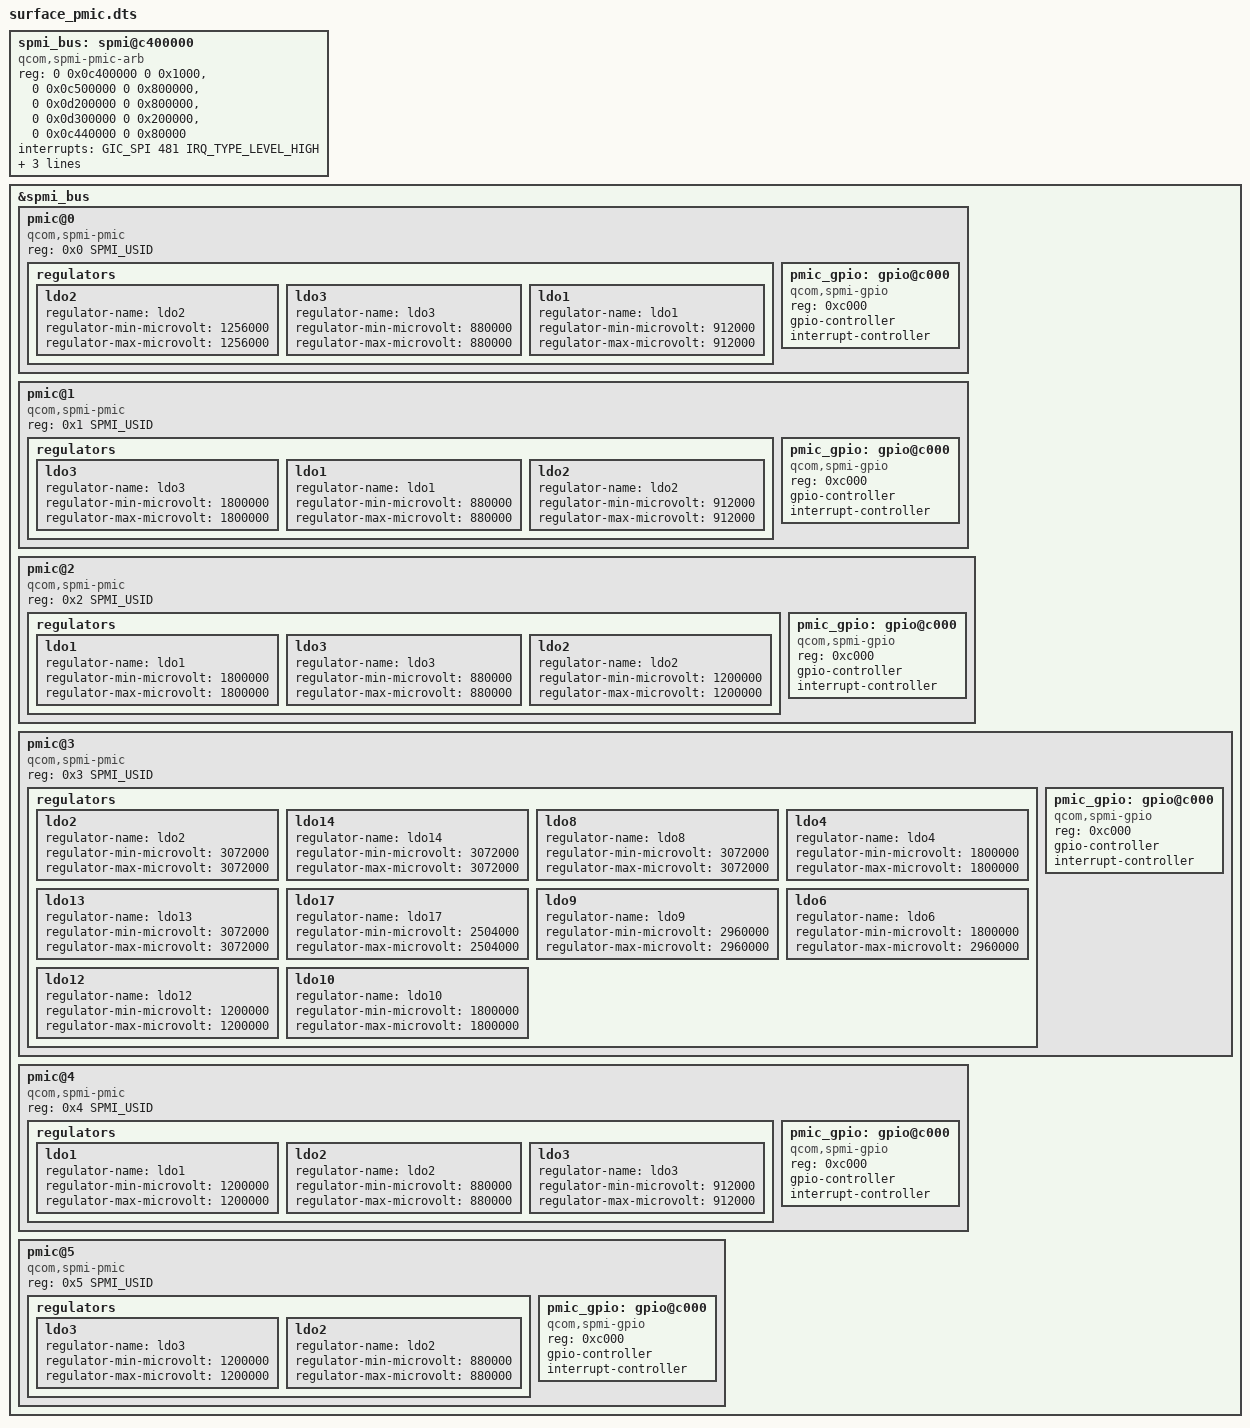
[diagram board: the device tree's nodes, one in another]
// Generated SPMI/PMIC Device Tree Configuration
// Based on parsed ACPI DSL files


spmi_bus: spmi@c400000 {
    compatible = "qcom,spmi-pmic-arb";
    reg = <0 0x0c400000 0 0x1000>,
          <0 0x0c500000 0 0x800000>,
          <0 0x0d200000 0 0x800000>,
          <0 0x0d300000 0 0x200000>,
          <0 0x0c440000 0 0x80000>;
    reg-names = "core", "chnls", "obsrvr", "intr", "cnfg";
    interrupt-names = "periph_irq";
    interrupts = <GIC_SPI 481 IRQ_TYPE_LEVEL_HIGH>;
    qcom,ee = <0>;
    qcom,channel = <0>;
    #address-cells = <2>;
    #size-cells = <0>;
    interrupt-controller;
    #interrupt-cells = <4>;
};


&spmi_bus {

    pmic@0 {
        compatible = "qcom,spmi-pmic";
        reg = <0x0 SPMI_USID>;
        #address-cells = <1>;
        #size-cells = <1>;
        
        regulators {
            ldo2: ldo2 {
                regulator-name = "ldo2";
                regulator-min-microvolt = <1256000>;
                regulator-max-microvolt = <1256000>;
            };
            ldo3: ldo3 {
                regulator-name = "ldo3";
                regulator-min-microvolt = <880000>;
                regulator-max-microvolt = <880000>;
            };
            ldo1: ldo1 {
                regulator-name = "ldo1";
                regulator-min-microvolt = <912000>;
                regulator-max-microvolt = <912000>;
            };
        };
        
        pmic_gpio: gpio@c000 {
            compatible = "qcom,spmi-gpio";
            reg = <0xc000>;
            gpio-controller;
            #gpio-cells = <2>;
            interrupt-controller;
            #interrupt-cells = <2>;
        };
    };
    pmic@1 {
        compatible = "qcom,spmi-pmic";
        reg = <0x1 SPMI_USID>;
        #address-cells = <1>;
        #size-cells = <1>;
        
        regulators {
            ldo3: ldo3 {
                regulator-name = "ldo3";
                regulator-min-microvolt = <1800000>;
                regulator-max-microvolt = <1800000>;
            };
            ldo1: ldo1 {
                regulator-name = "ldo1";
                regulator-min-microvolt = <880000>;
                regulator-max-microvolt = <880000>;
            };
            ldo2: ldo2 {
                regulator-name = "ldo2";
                regulator-min-microvolt = <912000>;
                regulator-max-microvolt = <912000>;
            };
        };
        
        pmic_gpio: gpio@c000 {
            compatible = "qcom,spmi-gpio";
            reg = <0xc000>;
            gpio-controller;
            #gpio-cells = <2>;
            interrupt-controller;
            #interrupt-cells = <2>;
        };
    };
    pmic@2 {
        compatible = "qcom,spmi-pmic";
        reg = <0x2 SPMI_USID>;
        #address-cells = <1>;
        #size-cells = <1>;
        
        regulators {
            ldo1: ldo1 {
                regulator-name = "ldo1";
                regulator-min-microvolt = <1800000>;
                regulator-max-microvolt = <1800000>;
            };
            ldo3: ldo3 {
                regulator-name = "ldo3";
                regulator-min-microvolt = <880000>;
                regulator-max-microvolt = <880000>;
            };
            ldo2: ldo2 {
                regulator-name = "ldo2";
                regulator-min-microvolt = <1200000>;
                regulator-max-microvolt = <1200000>;
            };
        };
        
        pmic_gpio: gpio@c000 {
            compatible = "qcom,spmi-gpio";
            reg = <0xc000>;
            gpio-controller;
            #gpio-cells = <2>;
            interrupt-controller;
            #interrupt-cells = <2>;
        };
    };
    pmic@3 {
        compatible = "qcom,spmi-pmic";
        reg = <0x3 SPMI_USID>;
        #address-cells = <1>;
        #size-cells = <1>;
        
        regulators {
            ldo2: ldo2 {
                regulator-name = "ldo2";
                regulator-min-microvolt = <3072000>;
                regulator-max-microvolt = <3072000>;
            };
            ldo14: ldo14 {
                regulator-name = "ldo14";
                regulator-min-microvolt = <3072000>;
                regulator-max-microvolt = <3072000>;
            };
            ldo8: ldo8 {
                regulator-name = "ldo8";
                regulator-min-microvolt = <3072000>;
                regulator-max-microvolt = <3072000>;
            };
            ldo4: ldo4 {
                regulator-name = "ldo4";
                regulator-min-microvolt = <1800000>;
                regulator-max-microvolt = <1800000>;
            };
            ldo13: ldo13 {
                regulator-name = "ldo13";
                regulator-min-microvolt = <3072000>;
                regulator-max-microvolt = <3072000>;
            };
            ldo17: ldo17 {
                regulator-name = "ldo17";
                regulator-min-microvolt = <2504000>;
                regulator-max-microvolt = <2504000>;
            };
            ldo9: ldo9 {
                regulator-name = "ldo9";
                regulator-min-microvolt = <2960000>;
                regulator-max-microvolt = <2960000>;
            };
            ldo6: ldo6 {
                regulator-name = "ldo6";
                regulator-min-microvolt = <1800000>;
                regulator-max-microvolt = <2960000>;
            };
            ldo12: ldo12 {
                regulator-name = "ldo12";
                regulator-min-microvolt = <1200000>;
                regulator-max-microvolt = <1200000>;
            };
            ldo10: ldo10 {
                regulator-name = "ldo10";
                regulator-min-microvolt = <1800000>;
                regulator-max-microvolt = <1800000>;
            };
        };
        
        pmic_gpio: gpio@c000 {
            compatible = "qcom,spmi-gpio";
            reg = <0xc000>;
            gpio-controller;
            #gpio-cells = <2>;
            interrupt-controller;
            #interrupt-cells = <2>;
        };
    };
    pmic@4 {
        compatible = "qcom,spmi-pmic";
        reg = <0x4 SPMI_USID>;
        #address-cells = <1>;
        #size-cells = <1>;
        
        regulators {
            ldo1: ldo1 {
                regulator-name = "ldo1";
                regulator-min-microvolt = <1200000>;
                regulator-max-microvolt = <1200000>;
            };
            ldo2: ldo2 {
                regulator-name = "ldo2";
                regulator-min-microvolt = <880000>;
                regulator-max-microvolt = <880000>;
            };
            ldo3: ldo3 {
                regulator-name = "ldo3";
                regulator-min-microvolt = <912000>;
                regulator-max-microvolt = <912000>;
            };
        };
        
        pmic_gpio: gpio@c000 {
            compatible = "qcom,spmi-gpio";
            reg = <0xc000>;
            gpio-controller;
            #gpio-cells = <2>;
            interrupt-controller;
            #interrupt-cells = <2>;
        };
    };
    pmic@5 {
        compatible = "qcom,spmi-pmic";
        reg = <0x5 SPMI_USID>;
        #address-cells = <1>;
        #size-cells = <1>;
        
        regulators {
            ldo3: ldo3 {
                regulator-name = "ldo3";
                regulator-min-microvolt = <1200000>;
                regulator-max-microvolt = <1200000>;
            };
            ldo2: ldo2 {
                regulator-name = "ldo2";
                regulator-min-microvolt = <880000>;
                regulator-max-microvolt = <880000>;
            };
        };
        
        pmic_gpio: gpio@c000 {
            compatible = "qcom,spmi-gpio";
            reg = <0xc000>;
            gpio-controller;
            #gpio-cells = <2>;
            interrupt-controller;
            #interrupt-cells = <2>;
        };
    };
};
